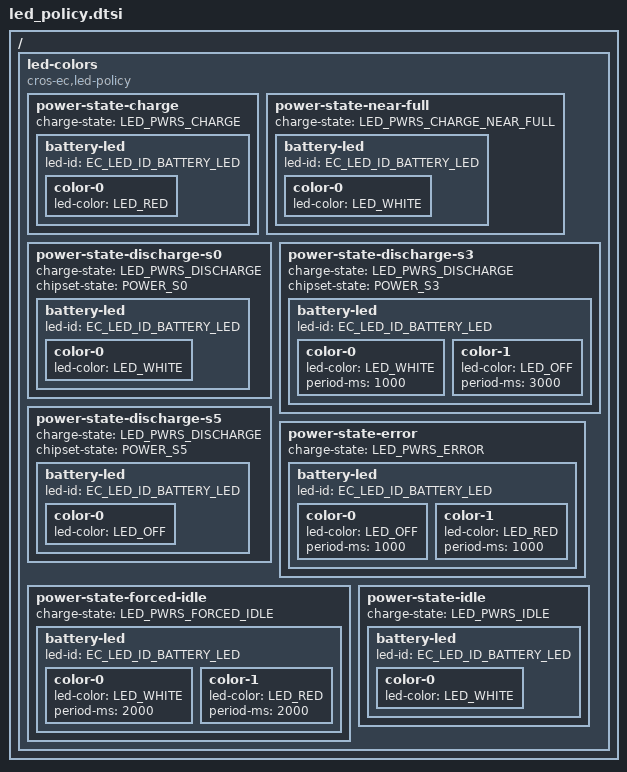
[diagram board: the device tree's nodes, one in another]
/* Copyright 2025 The ChromiumOS Authors
 * Use of this source code is governed by a BSD-style license that can be
 * found in the LICENSE file.
 */

 #include <dt-bindings/battery.h>

/ {
	led-colors {
		compatible = "cros-ec,led-policy";

		power-state-charge {
			charge-state = "LED_PWRS_CHARGE";

			battery-led {
				led-id = "EC_LED_ID_BATTERY_LED";

				color-0 {
					led-color = "LED_RED";
				};
			};
		};

		power-state-near-full {
			charge-state = "LED_PWRS_CHARGE_NEAR_FULL";

			battery-led {
				led-id = "EC_LED_ID_BATTERY_LED";

				color-0 {
					led-color = "LED_WHITE";
				};
			};
		};

		power-state-discharge-s0 {
			charge-state = "LED_PWRS_DISCHARGE";
			chipset-state = "POWER_S0";

			battery-led {
				led-id = "EC_LED_ID_BATTERY_LED";

				color-0 {
					led-color = "LED_WHITE";
				};
			};
		};
		power-state-discharge-s3 {
			charge-state = "LED_PWRS_DISCHARGE";
			chipset-state = "POWER_S3";

			battery-led {
				led-id = "EC_LED_ID_BATTERY_LED";

				color-0 {
					led-color = "LED_WHITE";
					period-ms = <1000>;
				};
				color-1 {
					led-color = "LED_OFF";
					period-ms = <3000>;
				};
			};
		};
		power-state-discharge-s5 {
			charge-state = "LED_PWRS_DISCHARGE";
			chipset-state = "POWER_S5";

			battery-led {
				led-id = "EC_LED_ID_BATTERY_LED";

				color-0 {
					led-color = "LED_OFF";
				};
			};
		};

		power-state-error {
			charge-state = "LED_PWRS_ERROR";

			battery-led {
				led-id = "EC_LED_ID_BATTERY_LED";

				color-0 {
					led-color = "LED_OFF";
					period-ms = <1000>;
				};
				color-1 {
					led-color = "LED_RED";
					period-ms = <1000>;
				};
			};
		};


		power-state-forced-idle {
			charge-state = "LED_PWRS_FORCED_IDLE";

			battery-led {
				led-id = "EC_LED_ID_BATTERY_LED";

				color-0 {
					led-color = "LED_WHITE";
					period-ms = <2000>;
				};
				color-1 {
					led-color = "LED_RED";
					period-ms = <2000>;
				};
			};
		};

		power-state-idle {
			charge-state = "LED_PWRS_IDLE";

			battery-led {
				led-id = "EC_LED_ID_BATTERY_LED";
				color-0 {
					led-color = "LED_WHITE";
				};
			};
		};
	};
};
